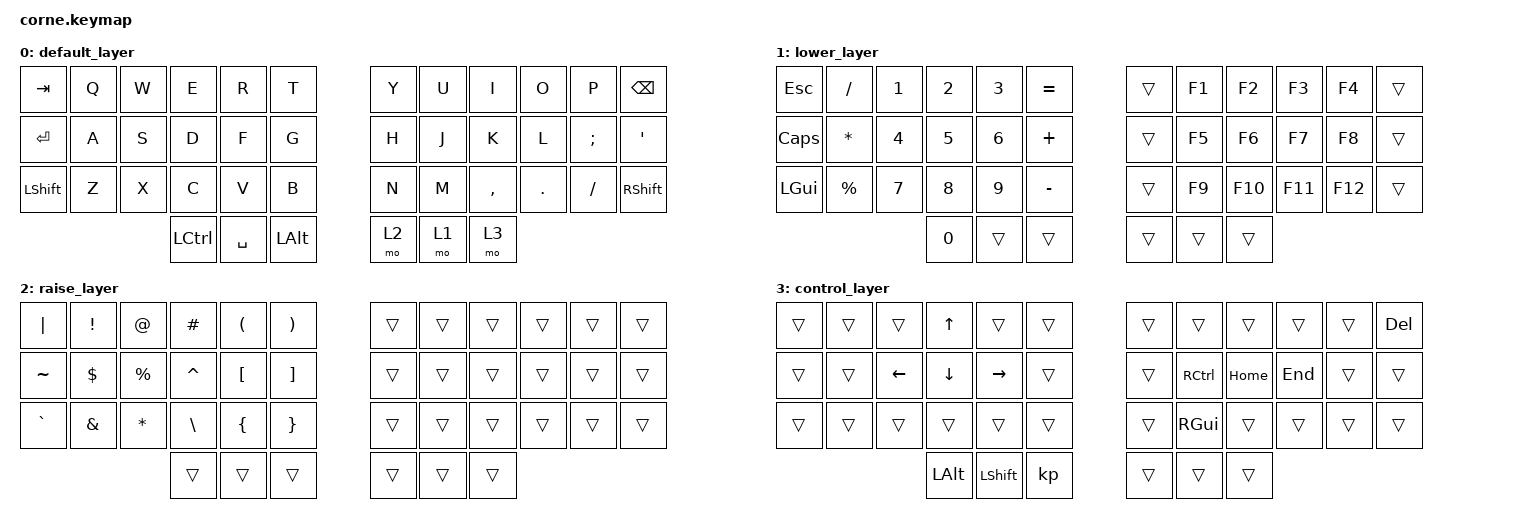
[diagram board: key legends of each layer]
/*
 * Copyright (c) 2020 The ZMK Contributors
 *
 * SPDX-License-Identifier: MIT
 */

#include <behaviors.dtsi>
#include <dt-bindings/zmk/keys.h>
#include <dt-bindings/zmk/bt.h>

/ {
        keymap {
                compatible = "zmk,keymap";

                default_layer {
// -----------------------------------------------------------------------------------------
// |  TAB |  Q  |  W  |  E  |  R  |  T  |   |  Y  |  U   |  I  |  O  |  P  | BKSP |
// | CTRL |  A  |  S  |  D  |  F  |  G  |   |  H  |  J   |  K  |  L  |  ;  |  '   |
// | SHFT |  Z  |  X  |  C  |  V  |  B  |   |  N  |  M   |  ,  |  .  |  /  | ESC  |
//                    | GUI | LWR | SPC |   | ENT | RSE  | ALT |
                        bindings = <
   &kp TAB   &kp Q &kp W &kp E &kp R &kp T        &kp Y &kp U  &kp I     &kp O   &kp P    &kp BSPC
   &kp ENTER &kp A &kp S &kp D &kp F &kp G         &kp H &kp J  &kp K     &kp L   &kp SEMI &kp SQT
   &kp LSHFT &kp Z &kp X &kp C &kp V &kp B        &kp N &kp M  &kp COMMA &kp DOT &kp FSLH &kp RSHFT
                &kp LCTRL &kp SPACE &kp LALT   &mo 2 &mo 1 &mo 3
                        >;
                };
                lower_layer {
// -----------------------------------------------------------------------------------------
// |  TAB |  1  |  2  |  3  |  4  |  5  |   |  6  |  7  |  8  |  9  |  0  | BKSP |
// | BTCLR| BT1 | BT2 | BT3 | BT4 | BT5 |   | LFT | DWN |  UP | RGT |     |      |
// | SHFT |     |     |     |     |     |   |     |     |     |     |     |      |
//                    | GUI |     | SPC |   | ENT |     | ALT |
                        bindings = <
   &kp ESC   &kp FSLH   &kp N1  &kp N2  &kp N3  &kp EQUAL        &trans   &kp F1   &kp F2   &kp F3  &kp F4   &trans
   &kp CAPS    &kp ASTRK  &kp N4  &kp N5  &kp N6  &kp PLUS       &trans   &kp F5   &kp F6   &kp F7  &kp F8   &trans
   &kp LGUI    &kp PRCNT  &kp N7  &kp N8  &kp N9  &kp MINUS        &trans   &kp F9   &kp F10  &kp F11 &kp F12  &trans
                                    &kp N0  &trans  &trans      &trans  &trans   &trans
                        >;
                };

                raise_layer {
// -----------------------------------------------------------------------------------------
// |  TAB |  !  |  @  |  #  |  $  |  %  |   |  ^  |  &  |  *  |  (  |  )  | BKSP |
// | CTRL |     |     |     |     |     |   |  -  |  =  |  [  |  ]  |  \  |  `   |
// | SHFT |     |     |     |     |     |   |  _  |  +  |  {  |  }  | "|" |  ~   |
//                    | GUI |     | SPC |   | ENT |     | ALT |
                        bindings = <
   &kp PIPE  &kp EXCL  &kp AT     &kp HASH  &kp LPAR &kp RPAR      &trans  &trans  &trans  &trans  &trans  &trans
   &kp TILDE &kp DLLR  &kp PRCNT  &kp CARET &kp LBKT &kp RBKT      &trans  &trans  &trans  &trans  &trans  &trans
   &kp GRAVE &kp AMPS  &kp ASTRK  &kp BSLH  &kp LBRC &kp RBRC      &trans  &trans  &trans  &trans  &trans  &trans    
                                         &trans  &trans  &trans   &trans  &trans  &trans
                        >;
                };

                control_layer {
// -----------------------------------------------------------------------------------------
// |  TAB |  1  |  2  |  3  |  4  |  5  |   |  6  |  7  |  8  |  9  |  0  | BKSP |
// | BTCLR| BT1 | BT2 | BT3 | BT4 | BT5 |   | LFT | DWN |  UP | RGT |     |      |
// | SHFT |     |     |     |     |     |   |     |     |     |     |     |      |
//                    | GUI |     | SPC |   | ENT |     | ALT |
                        bindings = <
   &trans   &trans   &trans    &kp UP     &trans      &trans             &trans   &trans         &trans   &trans   &trans   &kp DEL
   &trans   &trans   &kp LEFT  &kp DOWN   &kp RIGHT   &trans             &trans   &kp RCTRL      &kp HOME &kp END  &trans   &trans
   &trans   &trans   &trans    &trans     &trans      &trans             &trans   &kp RIGHT_GUI  &trans   &trans   &trans   &trans
                                    &kp LALT  &kp LSHIFT  &kp      &trans  &trans   &trans
                        >;
                };
        };
};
